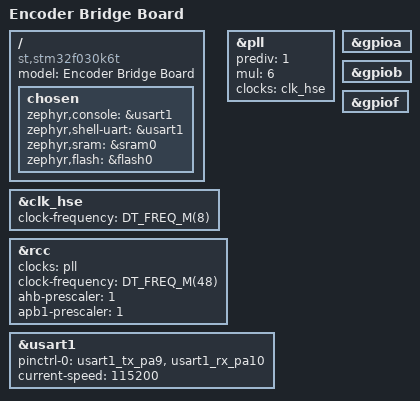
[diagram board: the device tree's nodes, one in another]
/dts-v1/;
#include <st/f0/stm32f030X6.dtsi>
#include <st/f0/stm32f030k6tx-pinctrl.dtsi>

/ {
	model = "Encoder Bridge Board";
	compatible = "st,stm32f030k6t";

	chosen {
		zephyr,console = &usart1;
		zephyr,shell-uart = &usart1;
		zephyr,sram = &sram0;
		zephyr,flash = &flash0;
	};
};

&clk_hse {
	clock-frequency = <DT_FREQ_M(8)>;
	status = "okay";
};

&pll {
	prediv = <1>;
	mul = <6>;
	clocks = <&clk_hse>;
	status = "okay";
};

&rcc {
	clocks = <&pll>;
	clock-frequency = <DT_FREQ_M(48)>;
	ahb-prescaler = <1>;
	apb1-prescaler = <1>;
};

&gpioa {
	status = "okay";
};

&gpiob {
	status = "okay";
};

&gpiof {
	status = "okay";
};

&usart1 {
	pinctrl-0 = <&usart1_tx_pa9 &usart1_rx_pa10>;
	pinctrl-names = "default";
	current-speed = <115200>;
	status = "okay";
};
